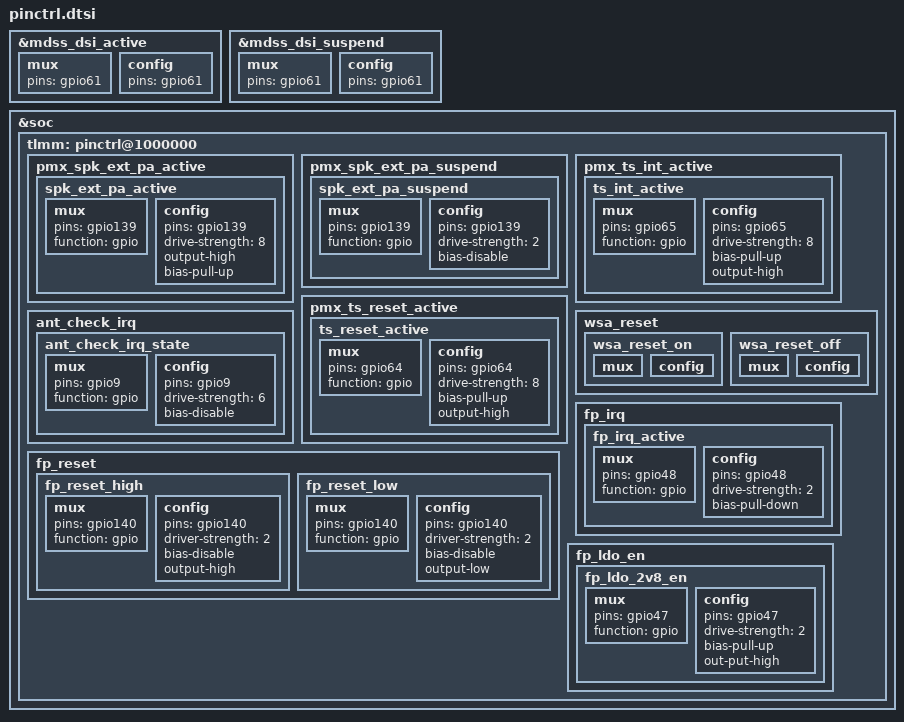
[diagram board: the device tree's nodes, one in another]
/* msm8953-pinctrl.dtsi */
&mdss_dsi_active {
    mux {
        pins = "gpio61";
    };
    config {
        pins = "gpio61";
    };
};
&mdss_dsi_suspend {
    mux {
        pins = "gpio61";
    };
    config {
        pins = "gpio61";
    };
};

/* msm8953-pinctrl */
&soc {
	tlmm: pinctrl@1000000 {
	    pmx_spk_ext_pa_active{
		spk_ext_pa_active: spk_ext_pa_active {
				mux {
					pins = "gpio139";
					function = "gpio";
				};

                config {
					pins = "gpio139";
					drive-strength = <8>;
					output-high;
					bias-pull-up;
				};
			};
		};
		pmx_spk_ext_pa_suspend{
			spk_ext_pa_suspend: spk_ext_pa_suspend {
				mux {
					pins = "gpio139";
					function = "gpio";
				};

                config {
					pins = "gpio139";
					drive-strength = <2>;
					bias-disable;
				};
			};
        };

		pmx_ts_int_active {
			ts_int_active: ts_int_active {
				mux {
					pins = "gpio65";
					function = "gpio";
				};

				config {
					pins = "gpio65";
					drive-strength = <8>;
					bias-pull-up;
					output-high;
				};
			};
		};

		pmx_ts_reset_active {
			ts_reset_active: ts_reset_active {
				mux {
					pins = "gpio64";
					function = "gpio";
				};

				config {
					pins = "gpio64";
					drive-strength = <8>;
					bias-pull-up;
					output-high;
				};
			};
		};

        wsa_reset {
			wsa_reset_on: wsa_reset_on {
				mux {
					/delete-property/pins;
				};

				config {
					/delete-property/pins;
				};
			};

			wsa_reset_off: wsa_reset_off {
				mux {
					/delete-property/pins;
				};

				config {
					/delete-property/pins;
				};
			};
		};

		// add by wangyibo for sar ant detect by wangyibo at 20190108 start
		ant_check_irq {
			ant_check_irq_state: ant_check_irq_state {
				mux {
					pins = "gpio9";
					function = "gpio";
				};

				config {
					pins = "gpio9";
					drive-strength = <6>;
					bias-disable;
				};
			};
		};

        fp_reset {
			fp_reset_high:fp_reset_high {
				mux {
					pins = "gpio140";
					function = "gpio";
				};

				config {
					pins = "gpio140";
					driver-strength = <2>;
					bias-disable;
					output-high;
				};
			};

			fp_reset_low:fp_reset_low {
				mux {
					pins = "gpio140";
					function = "gpio";
				};

				config {
					pins = "gpio140";
					driver-strength = <2>;
					bias-disable;
					output-low;
				};
			};
		};

		fp_irq {
			fp_irq_active:fp_irq_active {
				mux {
					pins = "gpio48";
					function = "gpio";
				};

				config {
					pins = "gpio48";
					drive-strength = <2>;
					bias-pull-down;
				};
			};
		};

		fp_ldo_en {
			fp_ldo_2v8_en:fp_ldo_2v8_en {
				mux {
					pins = "gpio47";
					function = "gpio";
				};

				config {
					pins = "gpio47";
					drive-strength = <2>;
					bias-pull-up;
					out-put-high;
				};
			};
		};
    };
};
